# ATSAMRH71F20C device description
Architecture: CORTEX-M7; Family: SAMRH; Series: SAMRH71
Registers are 32-bit, read-write, no defined reset value unless marked. A register's access mark holds for its fields unless they carry their own. Offsets are from the block's base; [hi:lo] are bit positions; {n}, {i} and the like mark numbered series.

## CHIPID — Chip Identifier
Instances: CHIPID 0x40100000
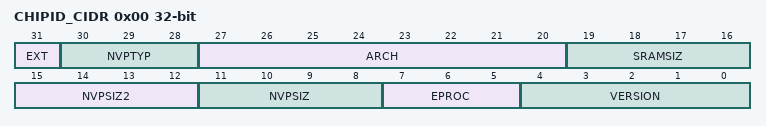
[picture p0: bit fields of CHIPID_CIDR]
0x00 CHIPID_CIDR ro — Chip ID Register
  [31] EXT — Extension Flag
  [30:28] NVPTYP — Nonvolatile Program Memory Type
    0=ROM; 1=ROMLESS (ROMless or on-chip Flash); 2=FLASH (Embedded Flash Memory); 3=ROM_FLASH (ROM and Embedded Flash Memory- NVPSIZ is ROM size- NVPSIZ2 is Flash size); 4=SRAM (SRAM emulating ROM)
  [27:20] ARCH — Architecture Identifier
    21=SAMU70SAMU71; 22=SAMV72
  [19:16] SRAMSIZ — Internal SRAM Size
    0=_48K (48 Kbytes); 1=_192K (192 Kbytes); 2=_384K (384 Kbytes); 3=_6K (6 Kbytes); 4=_24K (24 Kbytes); 5=_4K (4 Kbytes); 6=_80K (80 Kbytes); 7=_160K (160 Kbytes); 8=_8K (8 Kbytes); 9=_16K (16 Kbytes); 10=_32K (32 Kbytes); 11=_64K (64 Kbytes); 12=_128K (128 Kbytes); 13=_256K (256 Kbytes); 14=_96K (96 Kbytes); 15=_512K (512 Kbytes)
  [15:12] NVPSIZ2 — Second Nonvolatile Program Memory Size
    0=NONE; 1=_8K (8 Kbytes); 2=_16K (16 Kbytes); 3=_32K (32 Kbytes); 5=_64K (64 Kbytes); 7=_128K (128 Kbytes); 9=_256K (256 Kbytes); 10=_512K (512 Kbytes); 12=_1024K (1024 Kbytes); 14=_2048K (2048 Kbytes)
  [11:8] NVPSIZ — Nonvolatile Program Memory Size
    0=NONE; 1=_8K (8 Kbytes); 2=_16K (16 Kbytes); 3=_32K (32 Kbytes); 5=_64K (64 Kbytes); 7=_128K (128 Kbytes); 8=_160K (160 Kbytes); 9=_256K (256 Kbytes); 10=_512K (512 Kbytes); 12=_1024K (1024 Kbytes); 14=_2048K (2048 Kbytes)
  [7:5] EPROC — Embedded Processor
    0=SAMx7 (Cortex-M7); 1=ARM946ES; 2=ARM7TDMI; 3=CM3 (Cortex-M3); 4=ARM920T; 5=ARM926EJS; 6=CA5 (Cortex-A5); 7=CM4 (Cortex-M4)
  [4:0] VERSION — Version of the Device
0x04 CHIPID_EXID ro — Chip ID Extension Register
  [31:0] EXID — Chip ID Extension
    1=PACKAGE_TYPE_100 (100-lead package); 2=PACKAGE_TYPE_144 (144-lead package); 3=PACKAGE_TYPE_176 (176-lead package)

## FLEXRAMECC
Instances: FLEXRAMECC 0x40100600
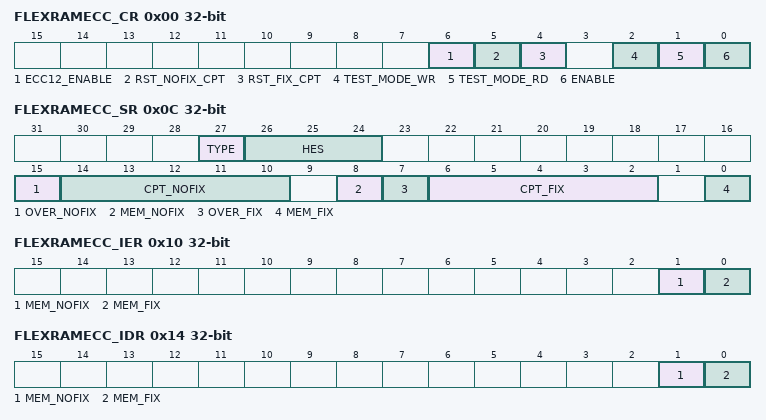
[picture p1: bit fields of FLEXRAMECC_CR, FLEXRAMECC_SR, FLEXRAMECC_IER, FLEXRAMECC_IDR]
0x00 FLEXRAMECC_CR — FLEXRAMECC Control Register
  [6] ECC12_ENABLE — BCH ECC enable
  [5] RST_NOFIX_CPT — reset the un-fixable error counter
  [4] RST_FIX_CPT — reset the fixable error counter
  [2] TEST_MODE_WR — test mode of ECC protection - write mode
  [1] TEST_MODE_RD — test mode of ECC protection - read mode
  [0] ENABLE — ECC protection enable
0x04 FLEXRAMECC_TESTCB1 — FLEXRAMECC Test mode register 1
  [7:0] TCB1 — Test Check Bit
0x0C FLEXRAMECC_SR ro — FLEXRAMECC Status register
  [27] TYPE — write or read access
  [26:24] HES — Hardware Error Size
  [15] OVER_NOFIX — counter overflow
  [14:10] CPT_NOFIX — 5 bits counter
  [8] MEM_NOFIX — Un-fixable error status
  [7] OVER_FIX — counter overflow
  [6:2] CPT_FIX — 5 bits counter
  [0] MEM_FIX — Fixable error status
0x10 FLEXRAMECC_IER wo — FLEXRAMECC Interrupt Enable Register
  [1] MEM_NOFIX — Un-fixable error
  [0] MEM_FIX — Fixable error
0x14 FLEXRAMECC_IDR wo — FLEXRAMECC Interrupt Disable Register
  [1] MEM_NOFIX — un-fixable error
  [0] MEM_FIX — fixable error
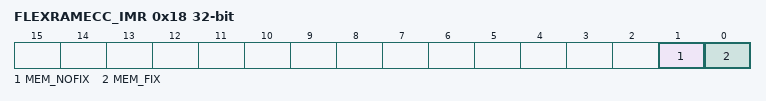
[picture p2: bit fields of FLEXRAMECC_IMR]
0x18 FLEXRAMECC_IMR ro — FLEXRAMECC Interrupt Mask Register
  [1] MEM_NOFIX — un-fixable error
  [0] MEM_FIX — fixable error
0x1C FLEXRAMECC_FAILAR ro — FLEXRAMECC Fail address register
  [31:0] ADDRESS — address of the error detected

## HEFC — Harden Embedded Flash Controller
Instances: HEFC 0x40004000
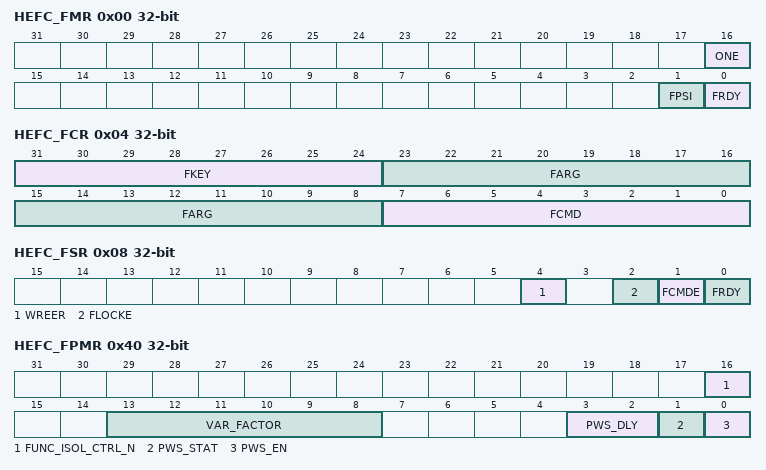
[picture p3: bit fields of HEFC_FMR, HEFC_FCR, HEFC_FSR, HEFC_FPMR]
0x00 HEFC_FMR — HEFC Flash Mode Register
  [16] ONE — Must be written to 1
  [1] FPSI — Flash Power Status Interrupt Enable
  [0] FRDY — Flash Ready Interrupt Enable
0x04 HEFC_FCR wo — HEFC Flash Command Register
  [31:24] FKEY — Flash Writing Protection Key
    90=PASSWD (The 0x5A value enables the command defined by the bits of the register. If the field is written with a different value, the write is not performed and no action is started.)
  [23:8] FARG — Flash Command Argument
  [7:0] FCMD — Flash Command
    0=GETD (Get Flash descriptor); 1=WP (Write page); 2=WPL (Write page and lock); 5=EA (Erase all); 6=EP (Erase page); 7=EPA (Erase pages); 8=SLB (Set lock bit); 9=CLB (Clear lock bit); 10=GLB (Get lock bit); 11=SGPB (Set GPNVM bit); 12=CGPB (Clear GPNVM bit); 13=GGPB (Get GPNVM bit); 16=GCALB (Get CALIB bit); 18=WUS (Write user signature); 19=EUS (Erase user signature); 20=STUS (Start read user signature); 21=SPUS (Stop read user signature)
0x08 HEFC_FSR ro — HEFC Flash Status Register
  [4] WREER — Write Register Error Status (cleared on read)
  [2] FLOCKE — Flash Lock Error Status (cleared on read)
  [1] FCMDE — Flash Command Error Status (cleared on read or by writing HEFC_FCR)
  [0] FRDY — Flash Ready Status (cleared when Flash is busy)
0x0C HEFC_FRR ro — HEFC Flash Result Register
  [31:0] FVALUE — Flash Result Value
0x40 HEFC_FPMR — HEFC Flash Power Management Register
  [16] FUNC_ISOL_CTRL_N — Flash insulated Control Status
  [13:8] VAR_FACTOR — Variation Factor
  [3:2] PWS_DLY — Power switch Delay
    0=_75US (delay is set to 75 usec); 1=_150US (delay is set to 150 usec); 2=_300US (delay is set to 300 usec); 3=_600US (delay is set to 600 usec)
  [1] PWS_STAT — Power switch Status
  [0] PWS_EN — Power switch enable
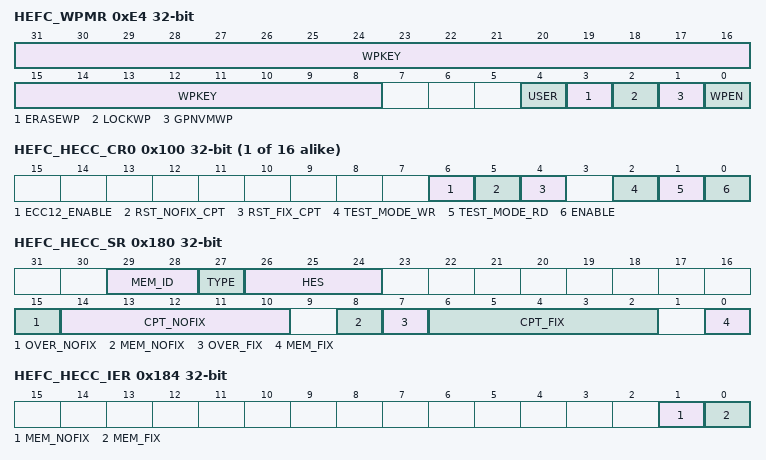
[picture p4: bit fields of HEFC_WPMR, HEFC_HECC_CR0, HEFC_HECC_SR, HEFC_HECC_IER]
0xE4 HEFC_WPMR — Write Protection Mode Register
  [31:8] WPKEY — Write Protection Key
    0x454643=PASSWD (Writing any other value in this field aborts the write operation.Always reads as 0.)
  [4] USER — User Signature Write Protection
  [3] ERASEWP — Page, Sector and Plane Write Protection
  [2] LOCKWP — Lock Bit Write Protection
  [1] GPNVMWP — GPNVM Bit Write Protection
  [0] WPEN — Write Protection Enable
{0x100+4i} HEFC_HECC_CR{i} (i=0..15) — HECC Control Register ChannelNumbers (ChannelNumbers = 0) {i}
  [6] ECC12_ENABLE — BCH ECC enable
  [5] RST_NOFIX_CPT — reset the un-fixable error counter
  [4] RST_FIX_CPT — reset the fixable error counter
  [2] TEST_MODE_WR — test mode of ECC protection - write mode
  [1] TEST_MODE_RD — test mode of ECC protection - read mode
  [0] ENABLE — ECC protection enable
{0x140+4i} HEFC_HECC_TESTCB{i} (i=0..15) — HECC Test mode ChannelNumbers (ChannelNumbers = 0) {i}
  [15:0] TCB — test check bit (16 bit)
0x180 HEFC_HECC_SR ro — HECC Status register
  [29:28] MEM_ID — memory identification number
  [27] TYPE — write or read access
  [26:24] HES — Hardware Error Size
  [15] OVER_NOFIX — counter overflow
  [14:10] CPT_NOFIX — 5 bits counter
  [8] MEM_NOFIX — Un-fixable error status
  [7] OVER_FIX — counter overflow
  [6:2] CPT_FIX — 5 bits counter
  [0] MEM_FIX — Fixable error status
0x184 HEFC_HECC_IER wo — HECC Interrupt Enable Register
  [1] MEM_NOFIX — Un-fixable error
  [0] MEM_FIX — Fixable error
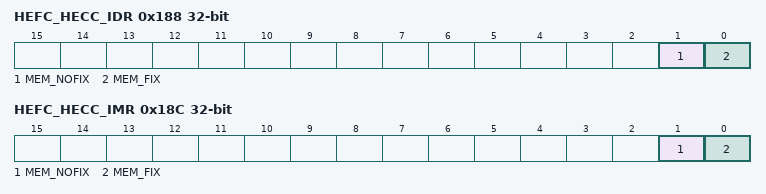
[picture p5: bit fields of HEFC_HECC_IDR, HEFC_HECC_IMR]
0x188 HEFC_HECC_IDR wo — HECC Interrupt Disable Register
  [1] MEM_NOFIX — un-fixable error
  [0] MEM_FIX — fixable error
0x18C HEFC_HECC_IMR ro — HECC Interrupt Mask Register
  [1] MEM_NOFIX — un-fixable error
  [0] MEM_FIX — fixable error
0x190 HEFC_HECC_FAILAR ro — HECC Fail address register
  [31:0] ADDRESS — address of the error detected

## Notices in the file
Copyright (c) 2018 Microchip Technology Inc.
SPDX-License-Identifier: Apache-2.0
Licensed under the Apache License, Version 2.0 (the "License");
you may not use this file except in compliance with the License.
You may obtain a copy of the License at
http://www.apache.org/licenses/LICENSE-2.0
Unless required by applicable law or agreed to in writing, software
distributed under the License is distributed on an "AS IS" BASIS,
WITHOUT WARRANTIES OR CONDITIONS OF ANY KIND, either express or implied.
See the License for the specific language governing permissions and
limitations under the License.
